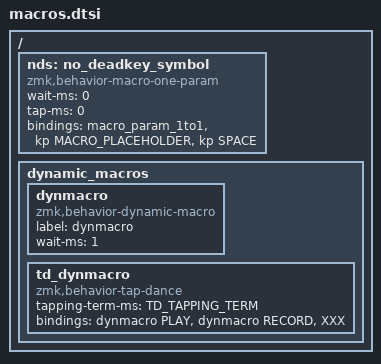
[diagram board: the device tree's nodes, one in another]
/*          40 KEY MATRIX / LAYOUT MAPPING
    ╭─────────────────────┬─────────────────────╮
╭───╯ LT4 LT3 LT2 LT1 LT0 │ RT0 RT1 RT2 RT3 RT4 ╰───╮
│ LM5 LM4 LM3 LM2 LM1 LM0 │ RM0 RM1 RM2 RM3 RM4 RM5 │
│ LB5 LB4 LB3 LB2 LB1 LB0 │ RB0 RB1 RB2 RB3 RB4 RB5 │
╰───────────╮ LH2 LH1 LH0 │ RH0 RH1 RH2 ╭───────────╯
╭───────────┴────────┬────┴──────────┬──┴──╮
│ WL  WD  WU  WR  WC │               │ ENC │
╰────────────────────╯               ╰─────╯*/

/ {
    nds: no_deadkey_symbol {
        compatible = "zmk,behavior-macro-one-param";
        wait-ms = <0>;
        tap-ms = <0>;
        #binding-cells = <1>;
        bindings
            = <&macro_param_1to1>
            , <&kp MACRO_PLACEHOLDER>
            , <&kp SPACE>
            ;
    };

    #define TAP_MACRO(NAME, BINDINGS) \
        NAME: NAME { \
			compatible = "zmk,behavior-macro"; \
            #binding-cells = <0>; \
            wait-ms = <0>; \
            tap-ms = <0>; \
            bindings = <&macro_tap BINDINGS>; \
        };

    #define MACRO(NAME, BINDINGS) \
        NAME: NAME { \
            compatible = "zmk,behavior-macro"; \
            #binding-cells = <0>; \
            wait-ms = <0>; \
            tap-ms = <0>; \
            bindings = <BINDINGS>; \
        };

    #define AUTOPAIR(NAME, OPENING_SYMBOL, CLOSING_SYMBOL) \
        TAP_MACRO(NAME ## _pair, OPENING_SYMBOL CLOSING_SYMBOL &kp LEFT) \
        TAP_MACRO(NAME ## _open, OPENING_SYMBOL &kp RET CLOSING_SYMBOL &kp UP &kp END &kp RET)

    TAP_MACRO(mc_cut, &kp LC(X))
    TAP_MACRO(mc_copy, &kp LC(C))
    TAP_MACRO(mc_paste, &kp LC(V))
    TAP_MACRO(mc_undo, &kp LC(Z))
    TAP_MACRO(mc_redo, &kp LC(Y))

    TAP_MACRO(mc_selword, &kp LC(LEFT) &kp LC(LS(RIGHT)))
    TAP_MACRO(mc_selline, &kp HOME &kp LS(END))

    TAP_MACRO(mc_dot_spc, &kp DOT &kp SPACE &sk LSHFT)

    TAP_MACRO(mc_braces, &kp END &kp LBRC &kp RBRC &kp LEFT &kp ENTER)

    dynamic_macros {
        dynmacro: dynmacro {
            compatible = "zmk,behavior-dynamic-macro";
            label = "dynmacro";
            #binding-cells = <1>;
            wait-ms = <1>;
        };

        td_dynmacro: td_dynmacro {
            compatible = "zmk,behavior-tap-dance";
            #binding-cells = <0>;
            tapping-term-ms = <TD_TAPPING_TERM>;
            bindings = <&dynmacro PLAY>, <&dynmacro RECORD>, <XXX>;
        };
    };
};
